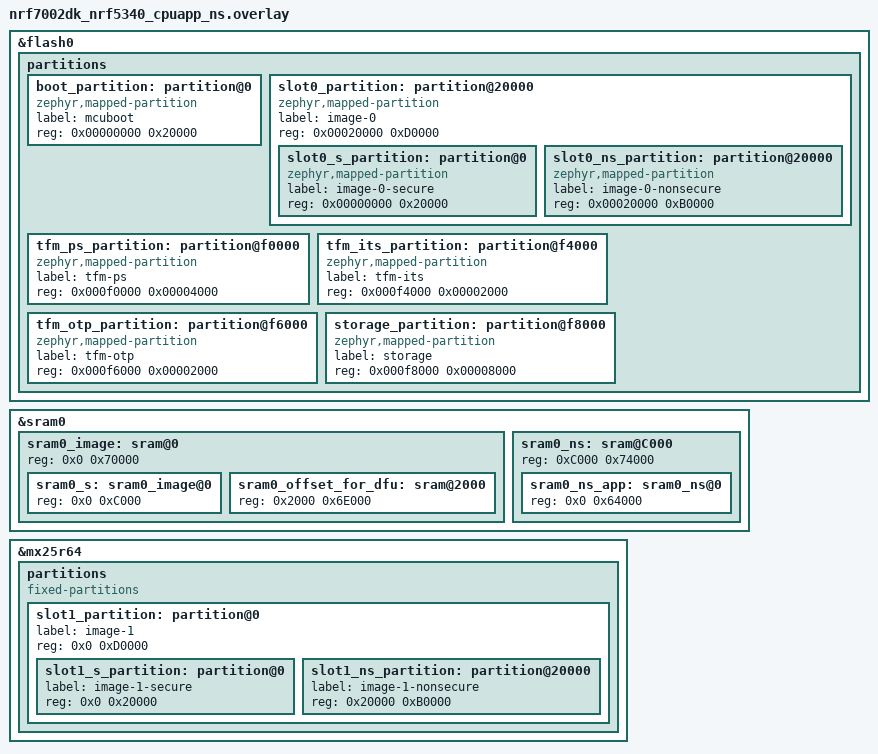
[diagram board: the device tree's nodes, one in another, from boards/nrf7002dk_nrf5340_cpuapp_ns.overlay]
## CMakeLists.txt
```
#
# Copyright (c) 2020 Nordic Semiconductor
#
# SPDX-License-Identifier: LicenseRef-Nordic-5-Clause
#

cmake_minimum_required(VERSION 3.20.0)

find_package(Zephyr REQUIRED HINTS $ENV{ZEPHYR_BASE})
project(nrf_connect_sdk_intermediate)

# NORDIC SDK APP START
target_sources(app PRIVATE src/main.c)
target_sources(app PRIVATE src/json_payload/json_payload.c)
# NORDIC SDK APP END

zephyr_include_directories(src)
zephyr_include_directories(src/json_payload)

# Make folder containing certificates global so that it can be located by the MQTT helper library.
zephyr_include_directories_ifdef(CONFIG_MQTT_HELPER_PROVISION_CERTIFICATES certs)
```

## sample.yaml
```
sample:
  description: nRF Connect SDK Intermediate Course by Nordic Developer Academy (https://academy.nordicsemi.com/)
  name: nRF Connect SDK Intermediate Course - Lesson 9 Exercise 7
  
common: 
    sysbuild: true
    build_only: true
    skip: true
    integration_platforms: 
      - nrf7002dk/nrf5340/cpuapp/ns
    platform_exclude:
      - native_sim
    
tests:
  ncs_inter.l9.e7: {}
```

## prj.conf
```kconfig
#
# Copyright (c) 2020 Nordic Semiconductor ASA
#
# SPDX-License-Identifier: LicenseRef-Nordic-5-Clause
#

# General
CONFIG_LOG=y
CONFIG_LOG_BUFFER_SIZE=2048
CONFIG_HW_ID_LIBRARY=y
CONFIG_ASSERT=y
CONFIG_JSON_LIBRARY=y
CONFIG_REBOOT=y

# Heap and stacks
CONFIG_HEAP_MEM_POOL_SIZE=8192
CONFIG_MAIN_STACK_SIZE=4096
CONFIG_SYSTEM_WORKQUEUE_STACK_SIZE=2048

# Network
CONFIG_NETWORKING=y
CONFIG_NET_NATIVE=y
CONFIG_NET_IPV4=y
CONFIG_NET_CONNECTION_MANAGER=y
CONFIG_ZVFS_OPEN_MAX=24 

# AWS IoT library
CONFIG_AWS_IOT=y

# STEP 3.2 - Add AWS host 
CONFIG_AWS_IOT_BROKER_HOST_NAME="xxx.amazonaws.com"

# STEP 4.2 - Add AWS thing name 
CONFIG_AWS_IOT_CLIENT_ID_STATIC=""

CONFIG_AWS_IOT_TOPIC_UPDATE_DELTA_SUBSCRIBE=y
CONFIG_AWS_IOT_TOPIC_GET_ACCEPTED_SUBSCRIBE=y
CONFIG_AWS_IOT_TOPIC_GET_REJECTED_SUBSCRIBE=y


# MQTT helper library
CONFIG_MQTT_HELPER=y
CONFIG_MQTT_HELPER_SEC_TAG=201
CONFIG_MQTT_HELPER_LAST_WILL=y
CONFIG_MQTT_HELPER_STACK_SIZE=4096

# MQTT - Maximum MQTT keepalive timeout specified by AWS IoT Core
CONFIG_MQTT_KEEPALIVE=1200
CONFIG_MQTT_CLEAN_SESSION=y

# STEP 1 - Configure the Wi-Fi credentials
CONFIG_WIFI_CREDENTIALS_STATIC=y
CONFIG_WIFI_CREDENTIALS_STATIC_SSID=""
CONFIG_WIFI_CREDENTIALS_STATIC_PASSWORD=""

# STEP 5.1 - Enable AWS FOTA
CONFIG_AWS_FOTA=y
CONFIG_AWS_FOTA_DOWNLOAD_SECURITY_TAG=201

# STEP 5.3 - Increment App version
CONFIG_AWS_IOT_SAMPLE_APP_VERSION="v1.0.0"
```

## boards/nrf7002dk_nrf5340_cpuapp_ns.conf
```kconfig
# Copyright (c) 2023 Nordic Semiconductor ASA
#
# SPDX-License-Identifier: LicenseRef-Nordic-5-Clause
#

# Configuration file for nRF7002 DK
# This file is merged with prj.conf in the application folder, and options
# set here will take precedence if they are present in both files.

# General
CONFIG_POSIX_TIMERS=y
CONFIG_SYSTEM_WORKQUEUE_STACK_SIZE=4096
CONFIG_HEAP_MEM_POOL_IGNORE_MIN=n
CONFIG_HW_STACK_PROTECTION=y
CONFIG_HW_ID_LIBRARY_SOURCE_NET_MAC=y
CONFIG_ZVFS_OPEN_MAX=25
CONFIG_MAIN_STACK_SIZE=6144

# Optimize Wi-Fi stack to save some memory
CONFIG_NRF70_RX_NUM_BUFS=16
CONFIG_NRF70_MAX_TX_AGGREGATION=4

# Wi-Fi
CONFIG_WIFI=y
CONFIG_WIFI_NRF70=y
CONFIG_WIFI_CREDENTIALS=y
CONFIG_FLASH=y
CONFIG_FLASH_PAGE_LAYOUT=y
CONFIG_FLASH_MAP=y

# Shell
CONFIG_SHELL=y
CONFIG_SHELL_STACK_SIZE=6144

# WPA
CONFIG_WIFI_NM_WPA_SUPPLICANT=y

# NET sockets
CONFIG_NET_L2_ETHERNET=y
CONFIG_NET_UDP=y
CONFIG_NET_TCP=y
CONFIG_NET_SOCKETS_OFFLOAD=n
CONFIG_NET_DHCPV4=y
CONFIG_NET_CONTEXT_SNDTIMEO=y
CONFIG_NET_CONTEXT_RCVTIMEO=y
CONFIG_NET_RX_STACK_SIZE=2048

# DNS
CONFIG_DNS_RESOLVER=y
CONFIG_NET_SOCKETS_DNS_TIMEOUT=30000

# Make the MQTT helper library provision credentials prior to establishing a TLS connection.
# Credentials needs to be pasted into their respective entry under samples/net/aws_iot/certs/.
CONFIG_MQTT_HELPER_PROVISION_CERTIFICATES=y

# Native network stack
CONFIG_PSA_CRYPTO=y
CONFIG_MBEDTLS=y
CONFIG_MBEDTLS_ENABLE_HEAP=y
CONFIG_MBEDTLS_HEAP_SIZE=90000
CONFIG_MBEDTLS_SSL_SERVER_NAME_INDICATION=y

CONFIG_MBEDTLS_DECLARE_PRIVATE_IDENTIFIERS=y
CONFIG_MBEDTLS_MD_C=y
CONFIG_MBEDTLS_HMAC_DRBG_C=y
CONFIG_MBEDTLS_SHA256_C=y
CONFIG_MBEDTLS_ECP_C=y
CONFIG_MBEDTLS_CTR_DRBG_C=y
CONFIG_MBEDTLS_AES_C=y
CONFIG_MBEDTLS_ENTROPY_C=y
CONFIG_MBEDTLS_RSA_C=y
CONFIG_PSA_WANT_KEY_TYPE_RSA_KEY_PAIR_IMPORT=y
CONFIG_PSA_WANT_KEY_TYPE_RSA_KEY_PAIR_EXPORT=y
CONFIG_PSA_WANT_KEY_TYPE_RSA_KEY_PAIR_GENERATE=y
# Set MPI (Multiple Precision Integer) size limit to 512 bytes for handling of 4 kb certificates
# in cryptographic operations.
CONFIG_MBEDTLS_MPI_MAX_SIZE=512
# ECDH/ECDSA are needed for TLS handshake
CONFIG_PSA_WANT_ALG_ECDH=y
CONFIG_PSA_WANT_ALG_ECDSA=y

# NET Sockets
CONFIG_NET_SOCKETS_SOCKOPT_TLS=y

# TLS credentials
CONFIG_TLS_CREDENTIALS_BACKEND_PROTECTED_STORAGE=y


# NET Sockets
CONFIG_NET_SOCKETS_SOCKOPT_TLS=y
CONFIG_NET_SOCKETS_TLS_MAX_CONTEXTS=2

# Zephyr NET Connection Manager Connectivity layer.
CONFIG_L2_WIFI_CONNECTIVITY=y
CONFIG_L2_WIFI_CONNECTIVITY_AUTO_CONNECT=n
CONFIG_L2_WIFI_CONNECTIVITY_AUTO_DOWN=n

# Serial Peripheral Interface (SPI) - Used to communicate with the mx25r64 external flash memory.
CONFIG_SPI=y
CONFIG_SPI_NOR=y
CONFIG_SPI_NOR_SFDP_DEVICETREE=y
CONFIG_PM_OVERRIDE_EXTERNAL_DRIVER_CHECK=y

# Bootloader and FOTA related configurations

# MCUBOOT
CONFIG_MCUBOOT_IMG_MANAGER=y

# Image manager
CONFIG_IMG_MANAGER=y
CONFIG_STREAM_FLASH=y
CONFIG_IMG_ERASE_PROGRESSIVELY=y

# AWS FOTA
CONFIG_AWS_FOTA=y
CONFIG_FOTA_DOWNLOAD=y
CONFIG_DFU_TARGET=y

# Download client (needed by AWS FOTA)
CONFIG_DOWNLOADER=y
CONFIG_DOWNLOADER_STACK_SIZE=4096

# TLS credentials
CONFIG_TLS_CREDENTIALS_BACKEND_PROTECTED_STORAGE=y

# Optimize TF-M
CONFIG_TFM_PROFILE_TYPE_SMALL=y
```

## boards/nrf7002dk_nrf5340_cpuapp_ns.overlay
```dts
/*
 * Copyright (c) 2023 Nordic Semiconductor ASA
 *
 * SPDX-License-Identifier: LicenseRef-Nordic-5-Clause
 */

/*
 * Partition layout matching partitions.yml (PM disabled).
 *
 * Internal Flash (1 MB):
 *   0x000000 - 0x010000  mcuboot           (64 KB)
 *   0x010000 - 0x010200  mcuboot_pad       (512 B)
 *   0x010200 - 0x030000  tfm               (~128 KB)
 *   0x030000 - 0x0F4000  app               (784 KB)
 *   0x0F4000 - 0x0F6000  tfm_its           (8 KB)
 *   0x0F6000 - 0x0F8000  (empty)           (8 KB)
 *   0x0F8000 - 0x0FA000  tfm_otp_nv_ctr    (8 KB)
 *   0x0FA000 - 0x0FC000  (empty)           (8 KB)
 *   0x0FC000 - 0x100000  tfm_ps            (16 KB)
 *
 * External Flash (mx25r64):
 *   0x000000 - 0x0E4000  mcuboot_secondary (912 KB)
 *
 * SRAM (512 KB):
 *   0x20000000 - 0x2000C000  tfm_sram      (48 KB)
 *   0x2000C000 - 0x20070000  sram_primary  (400 KB)
 *   0x20070000 - 0x20080000  rpmsg_nrf53   (64 KB)
 */

/* Delete default partitions from internal flash */
/delete-node/ &boot_partition;
/delete-node/ &slot1_partition;
/delete-node/ &slot0_partition;
/delete-node/ &sram0_image;
/delete-node/ &sram0_ns;

&flash0 {
	partitions {
		ranges;
		#address-cells = <1>;
		#size-cells = <1>;

		boot_partition: partition@0 {
			compatible = "zephyr,mapped-partition";
			label = "mcuboot";
			reg = <0x00000000 0x20000>;
		};

		slot0_partition: partition@20000 {
			compatible = "zephyr,mapped-partition";
			label = "image-0";
			reg = <0x00020000 0xD0000>;
			ranges = <0x0 0x20000 0xD0000>;
			#address-cells = <1>;
			#size-cells = <1>;

			slot0_s_partition: partition@0 {
				compatible = "zephyr,mapped-partition";
				label = "image-0-secure";
				reg = <0x00000000 0x20000>;
			};

			slot0_ns_partition: partition@20000 {
				compatible = "zephyr,mapped-partition";
				label = "image-0-nonsecure";
				reg = <0x00020000 0xB0000>;
			};
		};

		tfm_ps_partition: partition@f0000 {
			compatible = "zephyr,mapped-partition";
			label = "tfm-ps";
			reg = <0x000f0000 0x00004000>;
		};

		tfm_its_partition: partition@f4000 {
			compatible = "zephyr,mapped-partition";
			label = "tfm-its";
			reg = <0x000f4000 0x00002000>;
		};

		tfm_otp_partition: partition@f6000 {
			compatible = "zephyr,mapped-partition";
			label = "tfm-otp";
			reg = <0x000f6000 0x00002000>;
		};

		storage_partition: partition@f8000 {
			compatible = "zephyr,mapped-partition";
			label = "storage";
			reg = <0x000f8000 0x00008000>;
		};
	};
};

&sram0 {
	/* Default SRAM planning when building for nRF5340 with ARM TF-M support
	 * - Lowest 256 kB SRAM allocated to Secure image (sram0_s)
	 * - Upper 256 kB allocated to Non-Secure image (sram0_ns)
	 * Of the memory allocated to the Non-Secure image
	 * - 192 kB SRAM allocated to the Non-Secure application (sram0_ns_app).
	 * - 64 kB allocated to shared memory (sram0_shared).
	 *   (See nrf5340_shared_sram_partition.dtsi)
	 */
	sram0_image: sram@0 {
		/* Zephyr image(s) memory */
		reg = <0x0 0x70000>;
		ranges = <0x0 0x0 0x70000>;
		#address-cells = <1>;
		#size-cells = <1>;

		sram0_s: sram0_image@0 {
			/* Secure image memory — 48 KB for TF-M small profile */
			reg = <0x0 0xC000>;
		};

		sram0_offset_for_dfu: sram@2000 {
			reg = <0x2000 0x6E000>;
			ranges = <0x0 0x2000 0x6E000>;
			#address-cells = <1>;
			#size-cells = <1>;
		};
	};

	/*
	 * This is overlapping with the above part as this is used to set memory permissions to
	 * non-secure, the above outer partition is used for applications without TF-M support.
	 */
	sram0_ns: sram@C000 {
		/* Non-Secure image memory — starts after 48 KB TF-M SRAM */
		reg = <0xC000 0x74000>;
		ranges = <0x0 0xC000 0x74000>;
		#address-cells = <1>;
		#size-cells = <1>;

		sram0_ns_app: sram0_ns@0 {
			/* Non-Secure application memory — 400 KB */
			reg = <0x0 0x64000>;
		};
	};
};


&mx25r64 {
	status = "okay";
	partitions {
		compatible = "fixed-partitions";
		#address-cells = <1>;
		#size-cells = <1>;

		slot1_partition: partition@0 {
			label = "image-1";
			reg = <0x0 0xD0000>;
			ranges = <0x0 0x0 0xD0000>;
			#address-cells = <1>;
			#size-cells = <1>;

			slot1_s_partition: partition@0 {
				label = "image-1-secure";
				reg = <0x0 0x20000>;
			};

			slot1_ns_partition: partition@20000 {
				label = "image-1-nonsecure";
				reg = <0x20000 0xB0000>;
			};
		};
	};
};
```

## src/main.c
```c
/*
 * Copyright (c) 2020 Nordic Semiconductor ASA
 *
 * SPDX-License-Identifier: LicenseRef-Nordic-5-Clause
 */

#include <zephyr/kernel.h>
#include <zephyr/sys/reboot.h>
#include <zephyr/dfu/mcuboot.h>
#include <zephyr/logging/log.h>
#include <zephyr/logging/log_ctrl.h>
#include <zephyr/net/conn_mgr_connectivity.h>
#include <zephyr/net/conn_mgr_monitor.h>
#include <net/aws_iot.h>
#include <stdio.h>
#include <stdlib.h>
#include <hw_id.h>
#include <modem/modem_info.h>

#include "json_payload.h"

/* Register log module */
LOG_MODULE_REGISTER(aws_iot_sample, CONFIG_AWS_IOT_SAMPLE_LOG_LEVEL);

/* Macros used to subscribe to specific Zephyr NET management events. */
#define L4_EVENT_MASK (NET_EVENT_L4_CONNECTED | NET_EVENT_L4_DISCONNECTED)
#define CONN_LAYER_EVENT_MASK (NET_EVENT_CONN_IF_FATAL_ERROR)

#define MODEM_FIRMWARE_VERSION_SIZE_MAX 50

/* Application specific topics. */
#define MY_CUSTOM_TOPIC_1 "my-custom-topic/example"
#define MY_CUSTOM_TOPIC_2 "my-custom-topic/example_2"

/* Macro called upon a fatal error, reboots the device. */
#define FATAL_ERROR()					\
	LOG_ERR("Fatal error! Rebooting the device.");	\
	LOG_PANIC();					\
	IF_ENABLED(CONFIG_REBOOT, (sys_reboot(0)))

/* Zephyr NET management event callback structures. */
static struct net_mgmt_event_callback l4_cb;
static struct net_mgmt_event_callback conn_cb;

/* Variable used to store the device's hardware ID. */
static char hw_id[HW_ID_LEN];

/* Forward declarations. */
static void shadow_update_work_fn(struct k_work *work);
static void connect_work_fn(struct k_work *work);
static void aws_iot_event_handler(const struct aws_iot_evt *const evt);

/* Work items used to control some aspects of the sample. */
static K_WORK_DELAYABLE_DEFINE(shadow_update_work, shadow_update_work_fn);
static K_WORK_DELAYABLE_DEFINE(connect_work, connect_work_fn);

/* Static functions */

static int app_topics_subscribe(void)
{
	int err;
	static const struct mqtt_topic topic_list[] = {
		{
			.topic.utf8 = MY_CUSTOM_TOPIC_1,
			.topic.size = strlen(MY_CUSTOM_TOPIC_1) - 1,
			.qos = MQTT_QOS_1_AT_LEAST_ONCE,
		},
		{
			.topic.utf8 = MY_CUSTOM_TOPIC_2,
			.topic.size = strlen(MY_CUSTOM_TOPIC_2) - 1,
			.qos = MQTT_QOS_1_AT_LEAST_ONCE,
		}
	};

	err = aws_iot_application_topics_set(topic_list, ARRAY_SIZE(topic_list));
	if (err) {
		LOG_ERR("aws_iot_application_topics_set, error: %d", err);
		FATAL_ERROR();
		return err;
	}

	return 0;
}

static int aws_iot_client_init(void)
{
	int err;

	err = aws_iot_init(aws_iot_event_handler);
	if (err) {
		LOG_ERR("AWS IoT library could not be initialized, error: %d", err);
		FATAL_ERROR();
		return err;
	}

	/* Add application specific non-shadow topics to the AWS IoT library.
	 * These topics will be subscribed to when connecting to the broker.
	 */
	err = app_topics_subscribe();
	if (err) {
		LOG_ERR("Adding application specific topics failed, error: %d", err);
		FATAL_ERROR();
		return err;
	}

	return 0;
}

/* System Workqueue handlers. */

static void shadow_update_work_fn(struct k_work *work)
{
	int err;
	char message[CONFIG_AWS_IOT_SAMPLE_JSON_MESSAGE_SIZE_MAX] = { 0 };
	struct payload payload = {
		.state.reported.uptime = k_uptime_get(),
		.state.reported.app_version = CONFIG_AWS_IOT_SAMPLE_APP_VERSION,
	};
	struct aws_iot_data tx_data = {
		.qos = MQTT_QOS_0_AT_MOST_ONCE,
		.topic.type = AWS_IOT_SHADOW_TOPIC_UPDATE,
	};

	if (IS_ENABLED(CONFIG_MODEM_INFO)) {
		char modem_version_temp[MODEM_FIRMWARE_VERSION_SIZE_MAX];

		err = modem_info_get_fw_version(modem_version_temp,
						ARRAY_SIZE(modem_version_temp));
		if (err) {
			LOG_ERR("modem_info_get_fw_version, error: %d", err);
			FATAL_ERROR();
			return;
		}

		payload.state.reported.modem_version = modem_version_temp;
	}

	err = json_payload_construct(message, sizeof(message), &payload);
	if (err) {
		LOG_ERR("json_payload_construct, error: %d", err);
		FATAL_ERROR();
		return;
	}

	tx_data.ptr = message;
	tx_data.len = strlen(message);

	LOG_INF("Publishing message: %s to AWS IoT shadow", message);

	err = aws_iot_send(&tx_data);
	if (err) {
		LOG_ERR("aws_iot_send, error: %d", err);
		FATAL_ERROR();
		return;
	}

	(void)k_work_reschedule(&shadow_update_work,
				K_SECONDS(CONFIG_AWS_IOT_SAMPLE_PUBLICATION_INTERVAL_SECONDS));
}

static void connect_work_fn(struct k_work *work)
{
	int err;
	const struct aws_iot_config config = {
		.client_id = hw_id,
	};

	LOG_INF("Connecting to AWS IoT");

	err = aws_iot_connect(&config);
	if (err == -EAGAIN) {
		LOG_INF("Connection attempt timed out, "
			"Next connection retry in %d seconds",
			CONFIG_AWS_IOT_SAMPLE_CONNECTION_RETRY_TIMEOUT_SECONDS);

		(void)k_work_reschedule(&connect_work,
				K_SECONDS(CONFIG_AWS_IOT_SAMPLE_CONNECTION_RETRY_TIMEOUT_SECONDS));
	} else if (err) {
		LOG_ERR("aws_iot_connect, error: %d", err);
		FATAL_ERROR();
	}
}

/* Functions that are executed on specific connection-related events. */

static void on_aws_iot_evt_connected(const struct aws_iot_evt *const evt)
{
	(void)k_work_cancel_delayable(&connect_work);

	/* If persistent session is enabled, the AWS IoT library will not subscribe to any topics.
	 * Topics from the last session will be used.
	 */
	if (evt->data.persistent_session) {
		LOG_WRN("Persistent session is enabled, using subscriptions "
			"from the previous session");
	}

	/* Mark image as working to avoid reverting to the former image after a reboot. */
#if defined(CONFIG_BOOTLOADER_MCUBOOT)
  LOG_INF("Confirming image");
	boot_write_img_confirmed();
#endif

	/* Start sequential updates to AWS IoT. */
	(void)k_work_reschedule(&shadow_update_work, K_NO_WAIT);
}

static void on_aws_iot_evt_disconnected(void)
{
	(void)k_work_cancel_delayable(&shadow_update_work);
	(void)k_work_reschedule(&connect_work, K_SECONDS(5));
}

static void on_aws_iot_evt_fota_done(const struct aws_iot_evt *const evt)
{
	int err;

	/* Tear down MQTT connection. */
	(void)aws_iot_disconnect();
	(void)k_work_cancel_delayable(&connect_work);

	/* If modem FOTA has been carried out, the modem needs to be reinitialized.
	 * This is carried out by bringing the network interface down/up.
	 */
	if (evt->data.image & DFU_TARGET_IMAGE_TYPE_ANY_MODEM) {
		LOG_INF("Modem FOTA done, reinitializing the modem");

		err = conn_mgr_all_if_down(true);
		if (err) {
			LOG_ERR("conn_mgr_all_if_down, error: %d", err);
			FATAL_ERROR();
			return;
		}

		err = conn_mgr_all_if_up(true);
		if (err) {
			LOG_ERR("conn_mgr_all_if_up, error: %d", err);
			FATAL_ERROR();
			return;
		}

		err = conn_mgr_all_if_connect(true);
		if (err) {
			LOG_ERR("conn_mgr_all_if_connect, error: %d", err);
			FATAL_ERROR();
			return;
		}

	} else if (evt->data.image & DFU_TARGET_IMAGE_TYPE_ANY_APPLICATION) {
		LOG_INF("Application FOTA done, rebooting");
		IF_ENABLED(CONFIG_REBOOT, (sys_reboot(0)));
	} else {
		LOG_WRN("Unexpected FOTA image type");
	}
}

static void on_net_event_l4_connected(void)
{
	(void)k_work_reschedule(&connect_work, K_SECONDS(5));
}

static void on_net_event_l4_disconnected(void)
{
	(void)aws_iot_disconnect();
	(void)k_work_cancel_delayable(&connect_work);
	(void)k_work_cancel_delayable(&shadow_update_work);
}

/* Event handlers */

static void aws_iot_event_handler(const struct aws_iot_evt *const evt)
{
	switch (evt->type) {
	case AWS_IOT_EVT_CONNECTING:
		LOG_INF("AWS_IOT_EVT_CONNECTING");
		break;
	case AWS_IOT_EVT_CONNECTED:
		LOG_INF("AWS_IOT_EVT_CONNECTED");
		on_aws_iot_evt_connected(evt);
		break;
	case AWS_IOT_EVT_DISCONNECTED:
		LOG_INF("AWS_IOT_EVT_DISCONNECTED");
		on_aws_iot_evt_disconnected();
		break;
	case AWS_IOT_EVT_DATA_RECEIVED:
		LOG_INF("AWS_IOT_EVT_DATA_RECEIVED");

		LOG_INF("Received message: \"%.*s\" on topic: \"%.*s\"", evt->data.msg.len,
									 evt->data.msg.ptr,
									 evt->data.msg.topic.len,
									 evt->data.msg.topic.str);
		break;
	case AWS_IOT_EVT_PUBACK:
		LOG_INF("AWS_IOT_EVT_PUBACK, message ID: %d", evt->data.message_id);
		break;
	case AWS_IOT_EVT_PINGRESP:
		LOG_INF("AWS_IOT_EVT_PINGRESP");
		break;
	case AWS_IOT_EVT_FOTA_START:
		LOG_INF("AWS_IOT_EVT_FOTA_START");
		break;
	case AWS_IOT_EVT_FOTA_ERASE_PENDING:
		LOG_INF("AWS_IOT_EVT_FOTA_ERASE_PENDING");
		break;
	case AWS_IOT_EVT_FOTA_ERASE_DONE:
		LOG_INF("AWS_FOTA_EVT_ERASE_DONE");
		break;
	case AWS_IOT_EVT_FOTA_DONE:
		LOG_INF("AWS_IOT_EVT_FOTA_DONE");
		on_aws_iot_evt_fota_done(evt);
		break;
	case AWS_IOT_EVT_FOTA_DL_PROGRESS:
		LOG_INF("AWS_IOT_EVT_FOTA_DL_PROGRESS, (%d%%)", evt->data.fota_progress);
		break;
	case AWS_IOT_EVT_ERROR:
		LOG_INF("AWS_IOT_EVT_ERROR, %d", evt->data.err);
				FATAL_ERROR();
		break;
	case AWS_IOT_EVT_FOTA_ERROR:
		LOG_INF("AWS_IOT_EVT_FOTA_ERROR");
		break;
	default:
		LOG_WRN("Unknown AWS IoT event type: %d", evt->type);
		break;
	}
}

static void l4_event_handler(struct net_mgmt_event_callback *cb,
			     uint64_t event,
			     struct net_if *iface)
{
	switch (event) {
	case NET_EVENT_L4_CONNECTED:
		LOG_INF("Network connectivity established");
		on_net_event_l4_connected();
		break;
	case NET_EVENT_L4_DISCONNECTED:
		LOG_INF("Network connectivity lost");
		on_net_event_l4_disconnected();
		break;
	default:
		/* Don't care */
		return;
	}
}

static void connectivity_event_handler(struct net_mgmt_event_callback *cb,
				       uint64_t event,
				       struct net_if *iface)
{
	if (event == NET_EVENT_CONN_IF_FATAL_ERROR) {
		LOG_ERR("NET_EVENT_CONN_IF_FATAL_ERROR");
		FATAL_ERROR();
		return;
	}
}

int main(void)
{
	LOG_INF("The AWS IoT sample started, version: %s", CONFIG_AWS_IOT_SAMPLE_APP_VERSION);

	int err;

	/* Setup handler for Zephyr NET Connection Manager events. */
	net_mgmt_init_event_callback(&l4_cb, l4_event_handler, L4_EVENT_MASK);
	net_mgmt_add_event_callback(&l4_cb);

	/* Setup handler for Zephyr NET Connection Manager Connectivity layer. */
	net_mgmt_init_event_callback(&conn_cb, connectivity_event_handler, CONN_LAYER_EVENT_MASK);
	net_mgmt_add_event_callback(&conn_cb);

	/* Connecting to the configured connectivity layer.
	 * Wi-Fi or LTE depending on the board that the sample was built for.
	 */
	LOG_INF("Bringing network interface up and connecting to the network");

	err = conn_mgr_all_if_up(true);
	if (err) {
		LOG_ERR("conn_mgr_all_if_up, error: %d", err);
		FATAL_ERROR();
		return err;
	}

		err = conn_mgr_all_if_connect(true);
	if (err) {
		LOG_ERR("conn_mgr_all_if_connect, error: %d", err);
		FATAL_ERROR();
		return err;
	}

	err = aws_iot_client_init();
	if (err) {
		LOG_ERR("aws_iot_client_init, error: %d", err);
		FATAL_ERROR();
		return err;
	}

	return 0;
}
```
